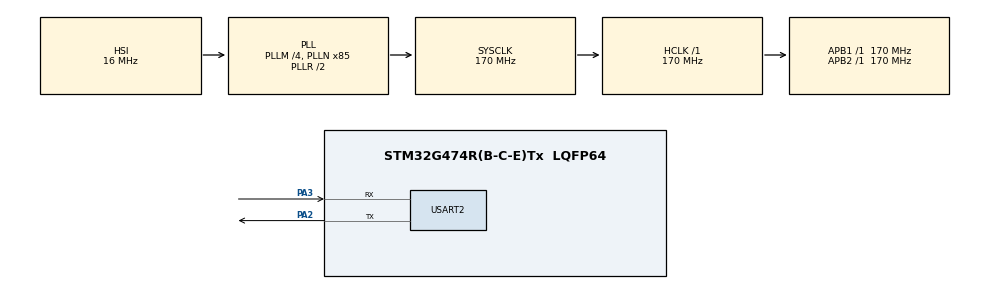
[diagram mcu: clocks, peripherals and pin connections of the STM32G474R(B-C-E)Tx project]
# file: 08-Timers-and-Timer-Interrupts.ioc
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Mcu.Family=STM32G4
Mcu.Name=STM32G474R(B-C-E)Tx
Mcu.Package=LQFP64
NUCLEO-G474RE.BUTTON=1
NUCLEO-G474RE.LD2=true
NVIC.EXTI15_10_IRQn=true\:0\:0\:false\:false\:true\:false\:true\:true
NVIC.PriorityGroup=NVIC_PRIORITYGROUP_4
NVIC.TIM1_UP_TIM16_IRQn=true\:0\:0\:false\:false\:true\:true\:true\:true
PA13.GPIO_Label=T_SWDIO
PA13.Signal=SYS_JTMS-SWDIO
PA14.GPIO_Label=T_SWCLK
PA14.Signal=SYS_JTCK-SWCLK
PA2.Mode=Asynchronous
PA2.Signal=USART2_TX
PA3.Mode=Asynchronous
PA3.Signal=USART2_RX
PB3.GPIO_Label=T_SWO
PB3.Signal=SYS_JTDO-SWO
PC0.GPIO_Label=LPUART1_RX [STLINKV3E_VCP_TX]
PC0.Signal=LPUART1_RX
PC1.GPIO_Label=LPUART1_TX [STLINKV3E_VCP_RX]
PC1.Signal=LPUART1_TX
PC14-OSC32_IN.GPIO_Label=RCC_OSC32_IN
PC14-OSC32_IN.Signal=RCC_OSC32_IN
PC15-OSC32_OUT.GPIO_Label=RCC_OSC32_OUT
PC15-OSC32_OUT.Signal=RCC_OSC32_OUT
PF0-OSC_IN.GPIO_Label=RCC_OSC_IN
PF0-OSC_IN.Signal=RCC_OSC_IN
PF1-OSC_OUT.GPIO_Label=RCC_OSC_OUT
PF1-OSC_OUT.Signal=RCC_OSC_OUT
ProjectManager.HeapSize=0x200
ProjectManager.StackSize=0x400
ProjectManager.TargetToolchain=STM32CubeIDE
RCC.ADC12Freq_Value=170000000
RCC.ADC345Freq_Value=170000000
RCC.AHBFreq_Value=170000000
RCC.APB1Freq_Value=170000000
RCC.APB1TimFreq_Value=170000000
RCC.APB2Freq_Value=170000000
RCC.APB2TimFreq_Value=170000000
RCC.CortexFreq_Value=170000000
RCC.EXTERNAL_CLOCK_VALUE=12288000
RCC.HCLKFreq_Value=170000000
RCC.HSE_VALUE=24000000
RCC.HSI48_VALUE=48000000
RCC.HSI_VALUE=16000000
RCC.LSE_VALUE=32768
RCC.PLLM=RCC_PLLM_DIV4
RCC.PLLN=85
RCC.RTCClockSelection=RCC_RTCCLKSOURCE_LSE
RCC.SYSCLKFreq_VALUE=170000000
RCC.SYSCLKSource=RCC_SYSCLKSOURCE_PLLCLK
RCC.USBFreq_Value=170000000
RCC.VCOOutputFreq_Value=340000000
TIM16.AutoReloadPreload=TIM_AUTORELOAD_PRELOAD_DISABLE
TIM16.PeriodNoDither=10000 - 1
TIM16.Prescaler=17000 - 1
USART2.VirtualMode-Asynchronous=VM_ASYNC
VP_NUCLEO-G474RE_VS_BSP_COMMON.Mode=COMMON
VP_SYS_VS_DBSignals.Mode=DisableDeadBatterySignals
VP_TIM16_VS_ClockSourceINT.Mode=Enable_Timer
board=NUCLEO-G474RE

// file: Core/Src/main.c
/* USER CODE BEGIN Header */
/**
  ******************************************************************************
  * @file           : main.c
  * @brief          : Main program body
  ******************************************************************************
  * @attention
  *
  * Copyright (c) 2026 STMicroelectronics.
  * All rights reserved.
  *
  * This software is licensed under terms that can be found in the LICENSE file
  * in the root directory of this software component.
  * If no LICENSE file comes with this software, it is provided AS-IS.
  *
  ******************************************************************************
  */
/* USER CODE END Header */
#include "main.h"

/* USER CODE BEGIN Includes */
#include <stdio.h>
/* USER CODE END Includes */

TIM_HandleTypeDef htim16;

UART_HandleTypeDef huart2;

void SystemClock_Config(void);
static void MX_GPIO_Init(void);
static void MX_TIM16_Init(void);
static void MX_USART2_UART_Init(void);

int main(void)
{

  /* USER CODE BEGIN 1 */
//  char uart_buf[50];
//  int uart_buf_len;
  uint16_t timer_val;
  /* USER CODE END 1 */

  /* MCU Configuration--------------------------------------------------------*/

  /* Reset of all peripherals, Initializes the Flash interface and the Systick. */
  HAL_Init();

  /* Configure the system clock */
  SystemClock_Config();

  /* Initialize all configured peripherals */
  MX_GPIO_Init();
  MX_TIM16_Init();
  MX_USART2_UART_Init();
  /* USER CODE BEGIN 2 */

//  // Say something
//  uart_buf_len = sprintf(uart_buf, "Timer Test\r\n");
//  HAL_UART_Transmit(&huart2, (uint8_t *)uart_buf, uart_buf_len, 100);
//
//  // Start timer
//  HAL_TIM_Base_Start(&htim16);

  // Start timer
  HAL_TIM_Base_Start_IT(&htim16);

  /* USER CODE END 2 */

  /* Infinite loop */
  /* USER CODE BEGIN WHILE */
  while (1)
  {
//	// Get current time (microseconds)
//	timer_val = __HAL_TIM_GET_COUNTER(&htim16);
//
//	// Wait for 50 ms
//	HAL_GPIO_WritePin(GPIOA, GPIO_PIN_5, GPIO_PIN_SET);
//	HAL_Delay(50);
//	HAL_GPIO_WritePin(GPIOA, GPIO_PIN_5, GPIO_PIN_RESET);
//
//	// Get time elapsed
//	timer_val = __HAL_TIM_GET_COUNTER(&htim16) - timer_val;
//
//	// Show elapsed time
//	uart_buf_len = sprintf(uart_buf, "%u us\r\n", timer_val);
//	HAL_UART_Transmit(&huart2, (uint8_t *)uart_buf, uart_buf_len, 100);
//
//	// Wait again so we don't flood the Serial terminal
//	HAL_Delay(1000);

    /* USER CODE END WHILE */

  }
}

void SystemClock_Config(void)
{
  RCC_OscInitTypeDef RCC_OscInitStruct = {0};
  RCC_ClkInitTypeDef RCC_ClkInitStruct = {0};

  /** Configure the main internal regulator output voltage
  */
  HAL_PWREx_ControlVoltageScaling(PWR_REGULATOR_VOLTAGE_SCALE1_BOOST);

  /** Initializes the RCC Oscillators according to the specified parameters
  * in the RCC_OscInitTypeDef structure.
  */
  RCC_OscInitStruct.OscillatorType = RCC_OSCILLATORTYPE_HSI;
  RCC_OscInitStruct.HSIState = RCC_HSI_ON;
  RCC_OscInitStruct.HSICalibrationValue = RCC_HSICALIBRATION_DEFAULT;
  RCC_OscInitStruct.PLL.PLLState = RCC_PLL_ON;
  RCC_OscInitStruct.PLL.PLLSource = RCC_PLLSOURCE_HSI;
  RCC_OscInitStruct.PLL.PLLM = RCC_PLLM_DIV4;
  RCC_OscInitStruct.PLL.PLLN = 85;
  RCC_OscInitStruct.PLL.PLLP = RCC_PLLP_DIV2;
  RCC_OscInitStruct.PLL.PLLQ = RCC_PLLQ_DIV2;
  RCC_OscInitStruct.PLL.PLLR = RCC_PLLR_DIV2;
  if (HAL_RCC_OscConfig(&RCC_OscInitStruct) != HAL_OK)
  {
    Error_Handler();
  }

  /** Initializes the CPU, AHB and APB buses clocks
  */
  RCC_ClkInitStruct.ClockType = RCC_CLOCKTYPE_HCLK|RCC_CLOCKTYPE_SYSCLK
                              |RCC_CLOCKTYPE_PCLK1|RCC_CLOCKTYPE_PCLK2;
  RCC_ClkInitStruct.SYSCLKSource = RCC_SYSCLKSOURCE_PLLCLK;
  RCC_ClkInitStruct.AHBCLKDivider = RCC_SYSCLK_DIV1;
  RCC_ClkInitStruct.APB1CLKDivider = RCC_HCLK_DIV1;
  RCC_ClkInitStruct.APB2CLKDivider = RCC_HCLK_DIV1;

  if (HAL_RCC_ClockConfig(&RCC_ClkInitStruct, FLASH_LATENCY_4) != HAL_OK)
  {
    Error_Handler();
  }
}

static void MX_TIM16_Init(void)
{

  htim16.Instance = TIM16;
  htim16.Init.Prescaler = 17000 - 1;
  htim16.Init.CounterMode = TIM_COUNTERMODE_UP;
  htim16.Init.Period = 9999;
  htim16.Init.ClockDivision = TIM_CLOCKDIVISION_DIV1;
  htim16.Init.RepetitionCounter = 0;
  htim16.Init.AutoReloadPreload = TIM_AUTORELOAD_PRELOAD_DISABLE;
  if (HAL_TIM_Base_Init(&htim16) != HAL_OK)
  {
    Error_Handler();
  }

}

static void MX_USART2_UART_Init(void)
{

  huart2.Instance = USART2;
  huart2.Init.BaudRate = 115200;
  huart2.Init.WordLength = UART_WORDLENGTH_8B;
  huart2.Init.StopBits = UART_STOPBITS_1;
  huart2.Init.Parity = UART_PARITY_NONE;
  huart2.Init.Mode = UART_MODE_TX_RX;
  huart2.Init.HwFlowCtl = UART_HWCONTROL_NONE;
  huart2.Init.OverSampling = UART_OVERSAMPLING_16;
  huart2.Init.OneBitSampling = UART_ONE_BIT_SAMPLE_DISABLE;
  huart2.Init.ClockPrescaler = UART_PRESCALER_DIV1;
  huart2.AdvancedInit.AdvFeatureInit = UART_ADVFEATURE_NO_INIT;
  if (HAL_UART_Init(&huart2) != HAL_OK)
  {
    Error_Handler();
  }
  if (HAL_UARTEx_SetTxFifoThreshold(&huart2, UART_TXFIFO_THRESHOLD_1_8) != HAL_OK)
  {
    Error_Handler();
  }
  if (HAL_UARTEx_SetRxFifoThreshold(&huart2, UART_RXFIFO_THRESHOLD_1_8) != HAL_OK)
  {
    Error_Handler();
  }
  if (HAL_UARTEx_DisableFifoMode(&huart2) != HAL_OK)
  {
    Error_Handler();
  }

}

static void MX_GPIO_Init(void)
{
  GPIO_InitTypeDef GPIO_InitStruct = {0};

  /* GPIO Ports Clock Enable */
  __HAL_RCC_GPIOC_CLK_ENABLE();
  __HAL_RCC_GPIOF_CLK_ENABLE();
  __HAL_RCC_GPIOA_CLK_ENABLE();
  __HAL_RCC_GPIOB_CLK_ENABLE();

  /*Configure GPIO pins : LPUART1_RX_Pin LPUART1_TX_Pin */
  GPIO_InitStruct.Pin = LPUART1_RX_Pin|LPUART1_TX_Pin;
  GPIO_InitStruct.Mode = GPIO_MODE_AF_PP;
  GPIO_InitStruct.Pull = GPIO_NOPULL;
  GPIO_InitStruct.Speed = GPIO_SPEED_FREQ_LOW;
  GPIO_InitStruct.Alternate = GPIO_AF8_LPUART1;
  HAL_GPIO_Init(GPIOC, &GPIO_InitStruct);

}

/* USER CODE BEGIN 4 */

// Callback: timer has rolled over
void HAL_TIM_PeriodElapsedCallback(TIM_HandleTypeDef *htim)
{
  // Check which version of the timer triggered this callback and toggle LED
  if (htim == &htim16 )
  {
    HAL_GPIO_TogglePin(GPIOA, GPIO_PIN_5);
  }
}

/* USER CODE END 4 */

void Error_Handler(void)
{
  __disable_irq();
  while (1)
  {
  }
}
